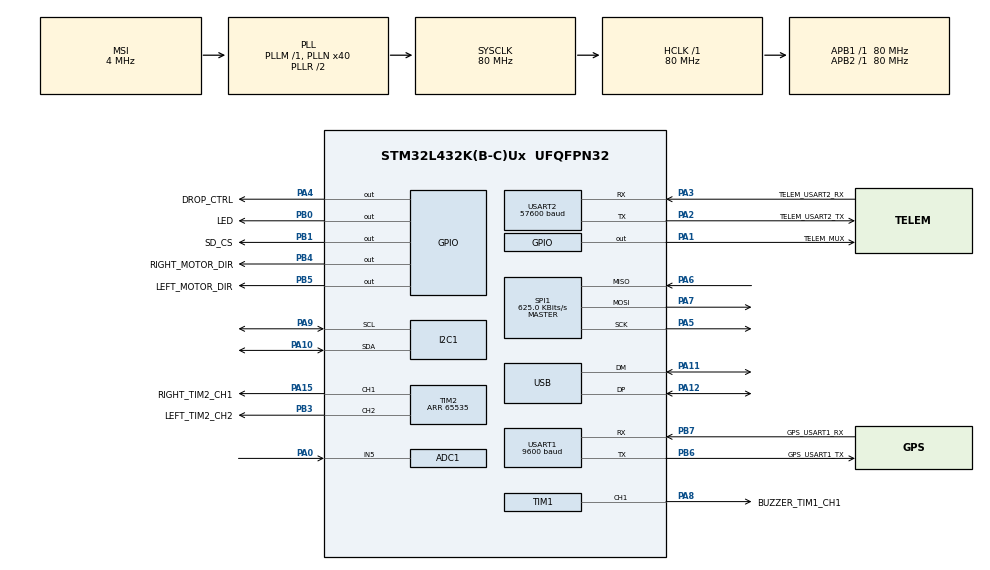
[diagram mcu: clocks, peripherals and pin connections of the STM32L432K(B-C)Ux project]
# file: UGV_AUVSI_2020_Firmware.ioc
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ADC1.Channel-4\#ChannelRegularConversion=ADC_CHANNEL_5
ADC1.NbrOfConversionFlag=1
ADC1.OffsetNumber-4\#ChannelRegularConversion=ADC_OFFSET_NONE
ADC1.Rank-4\#ChannelRegularConversion=1
ADC1.SamplingTime-4\#ChannelRegularConversion=ADC_SAMPLETIME_2CYCLES_5
ADC1.master=1
Dma.Request0=USART2_RX
Dma.USART2_RX.0.Direction=DMA_PERIPH_TO_MEMORY
Dma.USART2_RX.0.Instance=DMA1_Channel6
Dma.USART2_RX.0.MemDataAlignment=DMA_MDATAALIGN_BYTE
Dma.USART2_RX.0.MemInc=DMA_MINC_ENABLE
Dma.USART2_RX.0.Mode=DMA_CIRCULAR
Dma.USART2_RX.0.PeriphDataAlignment=DMA_PDATAALIGN_BYTE
Dma.USART2_RX.0.PeriphInc=DMA_PINC_DISABLE
Dma.USART2_RX.0.Priority=DMA_PRIORITY_LOW
FATFS._MULTI_PARTITION=1
Mcu.Family=STM32L4
Mcu.Name=STM32L432K(B-C)Ux
Mcu.Package=UFQFPN32
NVIC.ADC1_IRQn=true\:0\:0\:false\:false\:true\:true\:true
NVIC.DMA1_Channel6_IRQn=true\:0\:0\:false\:false\:true\:false\:true
NVIC.PriorityGroup=NVIC_PRIORITYGROUP_4
NVIC.TIM1_BRK_TIM15_IRQn=true\:0\:0\:false\:false\:true\:false\:true
NVIC.TIM1_UP_TIM16_IRQn=true\:0\:0\:false\:false\:true\:true\:true
NVIC.TimeBase=TIM1_BRK_TIM15_IRQn
NVIC.TimeBaseIP=TIM15
NVIC.USART1_IRQn=true\:0\:0\:false\:false\:true\:true\:true
NVIC.USB_IRQn=true\:0\:0\:false\:false\:true\:false\:true
PA0.Signal=ADCx_IN5
PA1.GPIO_Label=TELEM_MUX
PA1.Signal=GPIO_Output
PA10.GPIO_Pu=GPIO_PULLUP
PA10.Mode=I2C
PA10.Signal=I2C1_SDA
PA11.Mode=Device
PA11.Signal=USB_DM
PA12.Mode=Device
PA12.Signal=USB_DP
PA13\ (JTMS-SWDIO).Mode=Serial_Wire
PA13\ (JTMS-SWDIO).Signal=SYS_JTMS-SWDIO
PA14\ (JTCK-SWCLK).Mode=Serial_Wire
PA14\ (JTCK-SWCLK).Signal=SYS_JTCK-SWCLK
PA15\ (JTDI).GPIO_Label=RIGHT_TIM2_CH1
PA15\ (JTDI).Signal=S_TIM2_CH1
PA2.GPIO_Label=TELEM_USART2_TX
PA2.Mode=Asynchronous
PA2.Signal=USART2_TX
PA3.GPIO_Label=TELEM_USART2_RX
PA3.Mode=Asynchronous
PA3.Signal=USART2_RX
PA4.GPIO_Label=DROP_CTRL
PA4.Signal=GPIO_Output
PA5.Mode=Full_Duplex_Master
PA5.Signal=SPI1_SCK
PA6.Mode=Full_Duplex_Master
PA6.Signal=SPI1_MISO
PA7.Mode=Full_Duplex_Master
PA7.Signal=SPI1_MOSI
PA8.GPIO_Label=BUZZER_TIM1_CH1
PA8.Signal=S_TIM1_CH1
PA9.GPIO_Pu=GPIO_PULLUP
PA9.Mode=I2C
PA9.Signal=I2C1_SCL
PB0.GPIO_Label=LED
PB0.Signal=GPIO_Output
PB1.GPIO_Label=SD_CS
PB1.Signal=GPIO_Output
PB3\ (JTDO-TRACESWO).GPIO_Label=LEFT_TIM2_CH2
PB3\ (JTDO-TRACESWO).Signal=S_TIM2_CH2
PB4\ (NJTRST).GPIO_Label=RIGHT_MOTOR_DIR
PB4\ (NJTRST).Signal=GPIO_Output
PB5.GPIO_Label=LEFT_MOTOR_DIR
PB5.Signal=GPIO_Output
PB6.GPIO_Label=GPS_USART1_TX
PB6.Mode=Asynchronous
PB6.Signal=USART1_TX
PB7.GPIO_Label=GPS_USART1_RX
PB7.Mode=Asynchronous
PB7.Signal=USART1_RX
PC14-OSC32_IN\ (PC14).Mode=LSE-External-Oscillator
PC14-OSC32_IN\ (PC14).Signal=RCC_OSC32_IN
PC15-OSC32_OUT\ (PC15).Mode=LSE-External-Oscillator
PC15-OSC32_OUT\ (PC15).Signal=RCC_OSC32_OUT
ProjectManager.HeapSize=0x200
ProjectManager.StackSize=0x400
ProjectManager.TargetToolchain=STM32CubeIDE
RCC.ADCFreq_Value=48000000
RCC.AHBFreq_Value=80000000
RCC.APB1Freq_Value=80000000
RCC.APB1TimFreq_Value=80000000
RCC.APB2Freq_Value=80000000
RCC.APB2TimFreq_Value=80000000
RCC.CortexFreq_Value=80000000
RCC.HCLKFreq_Value=80000000
RCC.HSE_VALUE=8000000
RCC.HSI48_VALUE=48000000
RCC.HSI_VALUE=16000000
RCC.MSI_VALUE=4000000
RCC.PLLN=40
RCC.PLLSAI1N=24
RCC.SYSCLKFreq_VALUE=80000000
RCC.SYSCLKSource=RCC_SYSCLKSOURCE_PLLCLK
RCC.USBFreq_Value=48000000
RCC.VCOOutputFreq_Value=160000000
SH.ADCx_IN5.0=ADC1_IN5,IN5-Single-Ended
SH.S_TIM1_CH1.0=TIM1_CH1,PWM Generation1 CH1
SH.S_TIM2_CH1.0=TIM2_CH1,PWM Generation1 CH1
SH.S_TIM2_CH2.0=TIM2_CH2,PWM Generation2 CH2
SPI1.BaudRatePrescaler=SPI_BAUDRATEPRESCALER_128
SPI1.CalculateBaudRate=625.0 KBits/s
SPI1.DataSize=SPI_DATASIZE_8BIT
SPI1.Direction=SPI_DIRECTION_2LINES
SPI1.Mode=SPI_MODE_MASTER
SPI1.NSSPMode=SPI_NSS_PULSE_ENABLE
SPI1.VirtualType=VM_MASTER
TIM1.Channel-PWM\ Generation1\ CH1=TIM_CHANNEL_1
TIM1.Period=1000
TIM1.Prescaler=221
TIM16.Period=10000
TIM16.Prescaler=8000
TIM2.Channel-PWM\ Generation1\ CH1=TIM_CHANNEL_1
TIM2.Channel-PWM\ Generation2\ CH2=TIM_CHANNEL_2
TIM2.Period=65535
USART1.BaudRate=9600
USART1.SwapParam=ADVFEATURE_SWAP_DISABLE
USART1.VirtualMode-Asynchronous=VM_ASYNC
USART2.BaudRate=57600
USART2.SwapParam=ADVFEATURE_SWAP_DISABLE
USART2.VirtualMode-Asynchronous=VM_ASYNC
USB_DEVICE.CLASS_NAME_FS=CDC
USB_DEVICE.VirtualMode=Cdc
USB_DEVICE.VirtualModeFS=Cdc_FS
VP_CRC_VS_CRC.Mode=CRC_Activate
VP_FATFS_VS_Generic.Mode=User_defined
VP_SYS_VS_tim15.Mode=TIM15
VP_TIM16_VS_ClockSourceINT.Mode=Enable_Timer
VP_USB_DEVICE_VS_USB_DEVICE_CDC_FS.Mode=CDC_FS
board=custom

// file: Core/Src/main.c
/* USER CODE BEGIN Header */
/**
  ******************************************************************************
  * @file           : main.c
  * @brief          : Main program body
  ******************************************************************************
  * @attention
  *
  * <h2><center>&copy; Copyright (c) 2020 STMicroelectronics.
  * All rights reserved.</center></h2>
  *
  * This software component is licensed by ST under Ultimate Liberty license
  * SLA0044, the "License"; You may not use this file except in compliance with
  * the License. You may obtain a copy of the License at:
  *                             www.st.com/SLA0044
  *
  ******************************************************************************
  */
/* USER CODE END Header */
#include "main.h"
#include "adc.h"
#include "crc.h"
#include "dma.h"
#include "fatfs.h"
#include "i2c.h"
#include "spi.h"
#include "tim.h"
#include "usart.h"
#include "usb_device.h"
#include "gpio.h"

/* USER CODE BEGIN Includes */
#include "Application.h"
#include "buzzer.h"
#include "string.h"
#include "usbd_cdc_if.h"
/* USER CODE END Includes */

void SystemClock_Config(void);
void PeriphCommonClock_Config(void);

int main(void)
{

  /* MCU Configuration--------------------------------------------------------*/

  /* Reset of all peripherals, Initializes the Flash interface and the Systick. */
  HAL_Init();

  /* Configure the system clock */
  SystemClock_Config();

/* Configure the peripherals common clocks */
  PeriphCommonClock_Config();

  /* Initialize all configured peripherals */
  MX_GPIO_Init();
  MX_DMA_Init();
  MX_I2C1_Init();
  MX_SPI1_Init();
  MX_TIM1_Init();
  MX_TIM2_Init();
  MX_USART1_UART_Init();
  MX_USART2_UART_Init();
  MX_CRC_Init();
  MX_FATFS_Init();
  MX_USB_DEVICE_Init();
  MX_TIM16_Init();
  MX_ADC1_Init();
  /* USER CODE BEGIN 2 */

  ApplicationInit();

  /* USER CODE END 2 */

  /* Infinite loop */
  while (1)
  {

    /* USER CODE BEGIN 3 */
	ApplicationTask();
  }
  /* USER CODE END 3 */
}

void SystemClock_Config(void)
{
  RCC_OscInitTypeDef RCC_OscInitStruct = {0};
  RCC_ClkInitTypeDef RCC_ClkInitStruct = {0};

  /** Configure the main internal regulator output voltage
  */
  if (HAL_PWREx_ControlVoltageScaling(PWR_REGULATOR_VOLTAGE_SCALE1) != HAL_OK)
  {
    Error_Handler();
  }
  /** Configure LSE Drive Capability
  */
  HAL_PWR_EnableBkUpAccess();
  __HAL_RCC_LSEDRIVE_CONFIG(RCC_LSEDRIVE_LOW);
  /** Initializes the RCC Oscillators according to the specified parameters
  * in the RCC_OscInitTypeDef structure.
  */
  RCC_OscInitStruct.OscillatorType = RCC_OSCILLATORTYPE_LSE|RCC_OSCILLATORTYPE_MSI;
  RCC_OscInitStruct.LSEState = RCC_LSE_ON;
  RCC_OscInitStruct.MSIState = RCC_MSI_ON;
  RCC_OscInitStruct.MSICalibrationValue = 0;
  RCC_OscInitStruct.MSIClockRange = RCC_MSIRANGE_6;
  RCC_OscInitStruct.PLL.PLLState = RCC_PLL_ON;
  RCC_OscInitStruct.PLL.PLLSource = RCC_PLLSOURCE_MSI;
  RCC_OscInitStruct.PLL.PLLM = 1;
  RCC_OscInitStruct.PLL.PLLN = 40;
  RCC_OscInitStruct.PLL.PLLP = RCC_PLLP_DIV7;
  RCC_OscInitStruct.PLL.PLLQ = RCC_PLLQ_DIV2;
  RCC_OscInitStruct.PLL.PLLR = RCC_PLLR_DIV2;
  if (HAL_RCC_OscConfig(&RCC_OscInitStruct) != HAL_OK)
  {
    Error_Handler();
  }
  /** Initializes the CPU, AHB and APB buses clocks
  */
  RCC_ClkInitStruct.ClockType = RCC_CLOCKTYPE_HCLK|RCC_CLOCKTYPE_SYSCLK
                              |RCC_CLOCKTYPE_PCLK1|RCC_CLOCKTYPE_PCLK2;
  RCC_ClkInitStruct.SYSCLKSource = RCC_SYSCLKSOURCE_PLLCLK;
  RCC_ClkInitStruct.AHBCLKDivider = RCC_SYSCLK_DIV1;
  RCC_ClkInitStruct.APB1CLKDivider = RCC_HCLK_DIV1;
  RCC_ClkInitStruct.APB2CLKDivider = RCC_HCLK_DIV1;

  if (HAL_RCC_ClockConfig(&RCC_ClkInitStruct, FLASH_LATENCY_4) != HAL_OK)
  {
    Error_Handler();
  }
  /** Enable MSI Auto calibration
  */
  HAL_RCCEx_EnableMSIPLLMode();
}

void PeriphCommonClock_Config(void)
{
  RCC_PeriphCLKInitTypeDef PeriphClkInit = {0};

  /** Initializes the peripherals clock
  */
  PeriphClkInit.PeriphClockSelection = RCC_PERIPHCLK_USB|RCC_PERIPHCLK_ADC;
  PeriphClkInit.AdcClockSelection = RCC_ADCCLKSOURCE_PLLSAI1;
  PeriphClkInit.UsbClockSelection = RCC_USBCLKSOURCE_PLLSAI1;
  PeriphClkInit.PLLSAI1.PLLSAI1Source = RCC_PLLSOURCE_MSI;
  PeriphClkInit.PLLSAI1.PLLSAI1M = 1;
  PeriphClkInit.PLLSAI1.PLLSAI1N = 24;
  PeriphClkInit.PLLSAI1.PLLSAI1P = RCC_PLLP_DIV7;
  PeriphClkInit.PLLSAI1.PLLSAI1Q = RCC_PLLQ_DIV2;
  PeriphClkInit.PLLSAI1.PLLSAI1R = RCC_PLLR_DIV2;
  PeriphClkInit.PLLSAI1.PLLSAI1ClockOut = RCC_PLLSAI1_48M2CLK|RCC_PLLSAI1_ADC1CLK;
  if (HAL_RCCEx_PeriphCLKConfig(&PeriphClkInit) != HAL_OK)
  {
    Error_Handler();
  }
}

void HAL_TIM_PeriodElapsedCallback(TIM_HandleTypeDef *htim)
{
  if (htim->Instance == TIM15) {
    HAL_IncTick();
  }
  /* USER CODE BEGIN Callback 1 */
  if (htim->Instance == TIM16)
  {
  	buzzerPlayNoteITCallback();
  }
  /* USER CODE END Callback 1 */
}

void Error_Handler(void)
{
}

/************************ (C) COPYRIGHT STMicroelectronics *****END OF FILE****/
